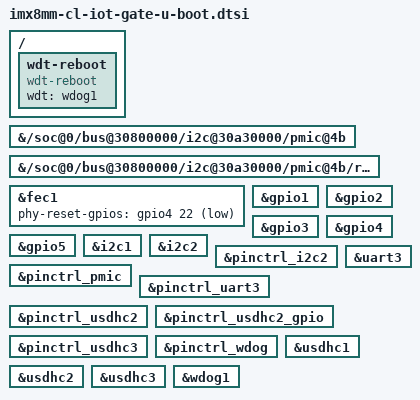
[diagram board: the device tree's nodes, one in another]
// SPDX-License-Identifier: GPL-2.0+
/*
 * Copyright 2019 NXP
 */

#include "imx8mm-u-boot.dtsi"

/ {
	wdt-reboot {
		compatible = "wdt-reboot";
		bootph-pre-ram;
		wdt = <&wdog1>;
	};
};

&{/soc@0/bus@30800000/i2c@30a30000/pmic@4b} {
	bootph-pre-ram;
};

&{/soc@0/bus@30800000/i2c@30a30000/pmic@4b/regulators} {
	bootph-pre-ram;
};

&fec1 {
	phy-reset-gpios = <&gpio4 22 GPIO_ACTIVE_LOW>;
};

&gpio1 {
	bootph-pre-ram;
};

&gpio2 {
	bootph-pre-ram;
};

&gpio3 {
	bootph-pre-ram;
};

&gpio4 {
	bootph-pre-ram;
};

&gpio5 {
	bootph-pre-ram;
};

&i2c1 {
	bootph-pre-ram;
};

&i2c2 {
	bootph-pre-ram;
};

&pinctrl_i2c2 {
	bootph-pre-ram;
};

&pinctrl_pmic {
	bootph-pre-ram;
};

&pinctrl_uart3 {
	bootph-pre-ram;
};

&pinctrl_usdhc2 {
	bootph-pre-ram;
};

&pinctrl_usdhc2_gpio {
	bootph-pre-ram;
};

&pinctrl_usdhc3 {
	bootph-pre-ram;
};

&pinctrl_wdog {
	bootph-pre-ram;
};

&uart3 {
	bootph-pre-ram;
};

&usdhc1 {
	bootph-pre-ram;
};

&usdhc2 {
	bootph-pre-ram;
};

&usdhc3 {
	bootph-pre-ram;
};

&wdog1 {
	bootph-pre-ram;
};
